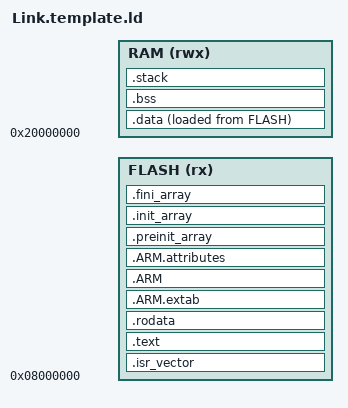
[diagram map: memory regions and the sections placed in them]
/* memory map */
MEMORY
{
  FLASH (rx)      : ORIGIN = 0x08000000, LENGTH = FLASH_SIZE
  RAM (rwx)       : ORIGIN = 0x20000000, LENGTH = RAM_SIZE
}

ENTRY(Reset_Handler)

/* Highest address of the user mode stack */
_estack = ORIGIN(RAM) + LENGTH(RAM);    /* end of RAM */
/* Generate a link error if heap and stack don't fit into RAM */
_Min_Heap_Size = 0x200;      /* required amount of heap  */
_Min_Stack_Size = 0x400; /* required amount of stack */

SECTIONS
{
  __stack_size = DEFINED(__stack_size) ? __stack_size : 2K;

  .isr_vector :
  {
    . = ALIGN(4);
    KEEP(*(.isr_vector)) /* Startup code */
    . = ALIGN(4);
  } >FLASH
 

  .text :
  {
    . = ALIGN(4);
    *(.text)
    *(.text*)
    *(.glue_7) 
    *(.glue_7t)
    *(.eh_frame)

    KEEP (*(.init))
    KEEP (*(.fini))

    . = ALIGN(4);
    /* the symbol _etext will be defined at the end of code section */
    _etext = .;
  } >FLASH

  .rodata :
  {
    . = ALIGN(4);
    *(.rodata)
    *(.rodata*)
    . = ALIGN(4);
  } >FLASH

   .ARM.extab :
  { 
     *(.ARM.extab* .gnu.linkonce.armextab.*) 
  } >FLASH
  
    .ARM : {
    __exidx_start = .;
      *(.ARM.exidx*)
      __exidx_end = .;
    } >FLASH

  .ARM.attributes : { *(.ARM.attributes) } > FLASH

  .preinit_array     :
  {
    PROVIDE_HIDDEN (__preinit_array_start = .);
    KEEP (*(.preinit_array*))
    PROVIDE_HIDDEN (__preinit_array_end = .);
  } >FLASH
  .init_array :
  {
    PROVIDE_HIDDEN (__init_array_start = .);
    KEEP (*(SORT(.init_array.*)))
    KEEP (*(.init_array*))
    PROVIDE_HIDDEN (__init_array_end = .);
  } >FLASH
  .fini_array :
  {
    PROVIDE_HIDDEN (__fini_array_start = .);
    KEEP (*(.fini_array*))
    KEEP (*(SORT(.fini_array.*)))
    PROVIDE_HIDDEN (__fini_array_end = .);
  } >FLASH



  /* provide some necessary symbols for startup file to initialize data */
  _sidata = LOADADDR(.data);
  .data :
  {
    . = ALIGN(4);
    /* the symbol _sdata will be defined at the data section end start */
    _sdata = .;
    *(.data)
    *(.data*)
    . = ALIGN(4);
    /* the symbol _edata will be defined at the data section end */
    _edata = .;
  } >RAM AT> FLASH

  . = ALIGN(4);
  .bss :
  {
    /* the symbol _sbss will be defined at the bss section start */
    _sbss = .;
    __bss_start__ = _sbss;
    *(.bss)
    *(.bss*)
    *(COMMON)
    . = ALIGN(4);
    /* the symbol _ebss will be defined at the bss section end */
    _ebss = .;
    __bss_end__ = _ebss;
  } >RAM

  PROVIDE ( end = _ebss );
  PROVIDE ( _end = _ebss );

  .stack ORIGIN(RAM) + LENGTH(RAM) - __stack_size :
  {
    PROVIDE( _heap_end = . );
    . = __stack_size;
    PROVIDE( _sp = . );
  } >RAM AT>RAM
}

 /* input sections */
GROUP(libgcc.a libc.a libm.a libnosys.a)
